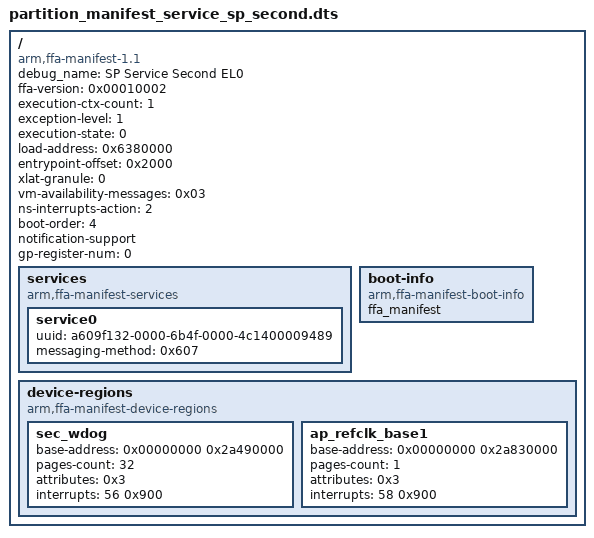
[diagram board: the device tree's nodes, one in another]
/*
 * Copyright 2021 The Hafnium Authors.
 *
 * Use of this source code is governed by a BSD-style
 * license that can be found in the LICENSE file or at
 * https://opensource.org/licenses/BSD-3-Clause.
 */

/dts-v1/;

/ {
  compatible = "arm,ffa-manifest-1.1";
  debug_name = "SP Service Second EL0";

  /* Properties */
  ffa-version = <0x00010002>; /* 31:16 - Major, 15:0 - Minor */
  execution-ctx-count = <1>;
  exception-level = <1>; /* S-EL0 */
  execution-state = <0>; /* AARCH64 */
  load-address = <0x6380000>;
  entrypoint-offset = <0x2000>;
  xlat-granule = <0>; /* 4KiB */
  vm-availability-messages = <0x03>; /* Supports VM created and VM destroyed messages. */
  ns-interrupts-action = <2>; /* NS interrupts are signaled */
  boot-order = <4>;
  notification-support; /* Receipt of notifications. */
  gp-register-num = <0>;

  services {
	compatible = "arm,ffa-manifest-services";

	service0 {
		uuid = "a609f132-0000-6b4f-0000-4c1400009489";
		messaging-method = <0x607>; /* Support direct (both APIs) and indirect messaging. */
	};
  };

  /* Boot Info */
  boot-info {
	compatible = "arm,ffa-manifest-boot-info";
	ffa_manifest;
  };

	device-regions {
		compatible = "arm,ffa-manifest-device-regions";

		sec_wdog {
			/* SP805 Trusted Watchdog Module */
			base-address = <0x00000000 0x2a490000>;
			pages-count = <32>; /* Two 64KB pages */
			attributes = <0x3>; /* read-write */
			interrupts = <56 0x900>;
		};

		ap_refclk_base1 {
			/* AP_REFCLK Generic System timer */
			base-address = <0x00000000 0x2a830000>;
			pages-count = <1>; /* One 4KB page */
			attributes = <0x3>; /* read-write */
			interrupts = <58 0x900>;
		};
	};
};
